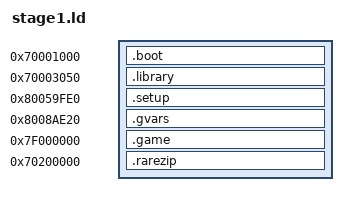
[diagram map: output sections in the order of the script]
/*OUTPUT_FORMAT ("elf32-bigmips")*/
OUTPUT_ARCH (mips)

SECTIONS
{
	setupSegmentStart = 0x80059fe0;
	setupSegmentRomStart = 0x39850;
	rarezipSegmentRomStart = 0x4e850;
	ziplistSegmentRomStart = 0x4fc40;

	.boot 0x70001000 : AT(0) {
		src/boot/boot.o (.text);
		src/boot/boot.o (.data);
	}

	.library 0x70003050 : AT(SIZEOF(.boot)) {
		src/library/library_03050.o (.text);
		src/library/library_034f0.o (.text);
		src/library/library_03ee0.o (.text);
		src/library/library_03fb0.o (.text);
		src/library/library_04320.o (.text);
		src/library/library_04790.o (.text);
		src/library/library_04840.o (.text);
		src/library/library_04a80.o (.text);
		src/library/library_05e40.o (.text);
		src/library/library_06100.o (.text);
		src/library/library_06330.o (.text);
		src/library/library_06440.o (.text);
		src/library/library_06550.o (.text);
		src/library/library_070d0.o (.text);
		src/library/library_074f0.o (.text);
		src/library/library_08a20.o (.text);
		src/library/library_09660.o (.text);
		src/library/library_0bfb0.o (.text);
		src/library/library_0c000.o (.text);
		src/library/library_0d0a0.o (.text);
		src/library/library_0d520.o (.text);
		src/library/library_0e9d0.o (.text);
		src/library/library_11420.o (.text);
		src/library/library_121e0.o (.text);
		src/library/library_126b0.o (.text);
		src/library/library_12dc0.o (.text);
		src/library/library_13130.o (.text);
		src/library/library_13710.o (.text);
		src/library/library_13750.o (.text);
		src/library/library_13790.o (.text);
		src/library/library_13900.o (.text);
		src/library/library_15860.o (.text);
		src/library/library_159b0.o (.text);
		src/library/library_16110.o (.text);
		src/library/library_1a500.o (.text);
		src/library/library_233c0.o (.text);
		src/library/library_2f490.o (.text);
		src/library/library_2fa00.o (.text);
		src/library/library_2faf0.o (.text);
		src/library/library_2fba0.o (.text);
		src/library/library_2fc60.o (.text);
		src/library/library_30ce0.o (.text);
		src/library/library_317f0.o (.text);
		src/library/library_37650.o (.text);
		src/library/library_37b00.o (.text);
		src/library/library_38d10.o (.text);
		src/library/library_38d30.o (.text);
		src/library/library_39c80.o (.text);
		src/library/library_39f70.o (.text);
		src/library/library_39fc0.o (.text);
		src/library/library_39fe0.o (.text);
		src/library/library_3a100.o (.text);
		src/library/library_3c430.o (.text);
		src/library/library_3c4d0.o (.text);
		src/library/library_3ccf0.o (.text);
		src/library/library_3cdc0.o (.text);
		src/library/library_3cef0.o (.text);
		src/library/library_3d280.o (.text);
		src/library/library_3e3e0.o (.text);
		src/library/library_3e730.o (.text);
		src/library/library_43dd0.o (.text);
		src/library/library_446d0.o (.text);
		src/library/library_44bc0.o (.text);
		src/library/library_44f60.o (.text);
		src/library/library_45ed0.o (.text);
		src/library/library_461c0.o (.text);
		src/library/library_46650.o (.text);
		src/library/library_47550.o (.text);
		src/library/library_47a90.o (.text);
		src/library/library_47d20.o (.text);
		src/library/library_48120.o (.text);
		src/library/library_48150.o (.text);
		src/library/library_481d0.o (.text);
		src/library/library_481e0.o (.text);
		src/library/library_48520.o (.text);
		src/library/library_485e0.o (.text);
		src/library/library_48650.o (.text);
		src/library/library_48830.o (.text);
		src/library/library_488e0.o (.text);
		src/library/library_48b20.o (.text);
		src/library/library_48c00.o (.text);
		src/library/library_48cd0.o (.text);
		src/library/library_48dc0.o (.text);
		src/library/library_48ef0.o (.text);
		src/library/library_48f50.o (.text);
		src/library/library_490b0.o (.text);
		src/library/library_491b0.o (.text);
		src/library/library_49640.o (.text);
		src/library/library_49780.o (.text);
		src/library/library_49a90.o (.text);
		src/library/library_49c20.o (.text);
		src/library/library_4a360.o (.text);
		src/library/library_4a5e0.o (.text);
		src/library/library_4a680.o (.text);
		src/library/library_4a810.o (.text);
		src/library/library_4a980.o (.text);
		src/library/library_4acc0.o (.text);
		src/library/library_4ace0.o (.text);
		src/library/library_4ad30.o (.text);
		src/library/library_4ad80.o (.text);
		src/library/library_4ae00.o (.text);
		src/library/library_4b160.o (.text);
		src/library/library_4b170.o (.text);
		src/library/library_4b480.o (.text);
		src/library/library_4b500.o (.text);
		src/library/library_4b550.o (.text);
		src/library/library_4b5e0.o (.text);
		src/library/library_4ba90.o (.text);
		src/library/library_4c090.o (.text);
		src/library/library_4cc10.o (.text);
		src/library/library_4cde0.o (.text);
		src/library/library_4ce60.o (.text);
		src/library/library_4d000.o (.text);
		src/library/library_4d480.o (.text);
		src/library/library_4d6f0.o (.text);
		src/library/library_4e270.o (.text);
		src/library/library_4e3c0.o (.text);
		src/library/library_4e470.o (.text);
		src/library/library_4e530.o (.text);
		src/library/library_4e690.o (.text);
		src/library/library_4f350.o (.text);
		src/library/library_4f400.o (.text);
		src/library/library_4f5e0.o (.text);
		src/library/library_4fe20.o (.text);
		src/library/library_4fff0.o (.text);
		src/library/library_50090.o (.text);
		src/library/library_50130.o (.text);
		src/library/library_50480.o (.text);
		src/library/library_50a00.o (.text);
		src/library/library_50f20.o (.text);
		src/library/library_513b0.o (.text);
		src/library/library_51880.o (.text);
		src/library/library_51890.o (.text);
		src/library/library_51900.o (.text);
		src/library/library_51a60.o (.text);
		src/library/library_51c10.o (.text);
		src/library/library_51c60.o (.text);
		src/library/library_51d50.o (.text);
		src/library/library_51ec0.o (.text);
		src/library/library_52070.o (.text);
		src/library/library_52360.o (.text);

		src/library/library_03050.o (.rodata);
		src/library/library_034f0.o (.rodata);
		src/library/library_03ee0.o (.rodata);
		src/library/library_03fb0.o (.rodata);
		src/library/library_04320.o (.rodata);
		src/library/library_04790.o (.rodata);
		src/library/library_04840.o (.rodata);
		src/library/library_04a80.o (.rodata);
		src/library/library_05e40.o (.rodata);
		src/library/library_06100.o (.rodata);
		src/library/library_06330.o (.rodata);
		src/library/library_06440.o (.rodata);
		src/library/library_06550.o (.rodata);
		src/library/library_070d0.o (.rodata);
		src/library/library_074f0.o (.rodata);
		src/library/library_08a20.o (.rodata);
		src/library/library_09660.o (.rodata);
		src/library/library_0bfb0.o (.rodata);
		src/library/library_0c000.o (.rodata);
		src/library/library_0d0a0.o (.rodata);
		src/library/library_0d520.o (.rodata);
		src/library/library_0e9d0.o (.rodata);
		src/library/library_11420.o (.rodata);
		src/library/library_121e0.o (.rodata);
		src/library/library_126b0.o (.rodata);
		src/library/library_12dc0.o (.rodata);
		src/library/library_13130.o (.rodata);
		src/library/library_13710.o (.rodata);
		src/library/library_13750.o (.rodata);
		src/library/library_13790.o (.rodata);
		src/library/library_13900.o (.rodata);
		src/library/library_15860.o (.rodata);
		src/library/library_159b0.o (.rodata);
		src/library/library_16110.o (.rodata);
		src/library/library_1a500.o (.rodata);
		src/library/library_233c0.o (.rodata);
		src/library/library_2f490.o (.rodata);
		src/library/library_2fa00.o (.rodata);
		src/library/library_2faf0.o (.rodata);
		src/library/library_2fba0.o (.rodata);
		src/library/library_2fc60.o (.rodata);
		src/library/library_30ce0.o (.rodata);
		src/library/library_317f0.o (.rodata);
		src/library/library_37650.o (.rodata);
		src/library/library_37b00.o (.rodata);
		src/library/library_38d10.o (.rodata);
		src/library/library_38d30.o (.rodata);
		src/library/library_39c80.o (.rodata);
		src/library/library_39f70.o (.rodata);
		src/library/library_39fc0.o (.rodata);
		src/library/library_39fe0.o (.rodata);
		src/library/library_3a100.o (.rodata);
		src/library/library_3c430.o (.rodata);
		src/library/library_3c4d0.o (.rodata);
		src/library/library_3ccf0.o (.rodata);
		src/library/library_3cdc0.o (.rodata);
		src/library/library_3cef0.o (.rodata);
		src/library/library_3d280.o (.rodata);
		src/library/library_3e3e0.o (.rodata);
		src/library/library_3e730.o (.rodata);
		src/library/library_43dd0.o (.rodata);
		src/library/library_446d0.o (.rodata);
		src/library/library_44bc0.o (.rodata);
		src/library/library_44f60.o (.rodata);
		src/library/library_45ed0.o (.rodata);
		src/library/library_461c0.o (.rodata);
		src/library/library_46650.o (.rodata);
		src/library/library_47550.o (.rodata);
		src/library/library_47a90.o (.rodata);
		src/library/library_47d20.o (.rodata);
		src/library/library_48120.o (.rodata);
		src/library/library_48150.o (.rodata);
		src/library/library_481d0.o (.rodata);
		src/library/library_481e0.o (.rodata);
		src/library/library_48520.o (.rodata);
		src/library/library_485e0.o (.rodata);
		src/library/library_48650.o (.rodata);
		src/library/library_48830.o (.rodata);
		src/library/library_488e0.o (.rodata);
		src/library/library_48b20.o (.rodata);
		src/library/library_48c00.o (.rodata);
		src/library/library_48cd0.o (.rodata);
		src/library/library_48dc0.o (.rodata);
		src/library/library_48ef0.o (.rodata);
		src/library/library_48f50.o (.rodata);
		src/library/library_490b0.o (.rodata);
		src/library/library_491b0.o (.rodata);
		src/library/library_49640.o (.rodata);
		src/library/library_49780.o (.rodata);
		src/library/library_49a90.o (.rodata);
		src/library/library_49c20.o (.rodata);
		src/library/library_4a360.o (.rodata);
		src/library/library_4a5e0.o (.rodata);
		src/library/library_4a680.o (.rodata);
		src/library/library_4a810.o (.rodata);
		src/library/library_4a980.o (.rodata);
		src/library/library_4acc0.o (.rodata);
		src/library/library_4ace0.o (.rodata);
		src/library/library_4ad30.o (.rodata);
		src/library/library_4ad80.o (.rodata);
		src/library/library_4ae00.o (.rodata);
		src/library/library_4b160.o (.rodata);
		src/library/library_4b170.o (.rodata);
		src/library/library_4b480.o (.rodata);
		src/library/library_4b500.o (.rodata);
		src/library/library_4b550.o (.rodata);
		src/library/library_4b5e0.o (.rodata);
		src/library/library_4ba90.o (.rodata);
		src/library/library_4c090.o (.rodata);
		src/library/library_4cc10.o (.rodata);
		src/library/library_4cde0.o (.rodata);
		src/library/library_4ce60.o (.rodata);
		src/library/library_4d000.o (.rodata);
		src/library/library_4d480.o (.rodata);
		src/library/library_4d6f0.o (.rodata);
		src/library/library_4e270.o (.rodata);
		src/library/library_4e3c0.o (.rodata);
		src/library/library_4e470.o (.rodata);
		src/library/library_4e530.o (.rodata);
		src/library/library_4e690.o (.rodata);
		src/library/library_4f350.o (.rodata);
		src/library/library_4f400.o (.rodata);
		src/library/library_4f5e0.o (.rodata);
		src/library/library_4fe20.o (.rodata);
		src/library/library_4fff0.o (.rodata);
		src/library/library_50090.o (.rodata);
		src/library/library_50130.o (.rodata);
		src/library/library_50480.o (.rodata);
		src/library/library_50a00.o (.rodata);
		src/library/library_50f20.o (.rodata);
		src/library/library_513b0.o (.rodata);
		src/library/library_51880.o (.rodata);
		src/library/library_51890.o (.rodata);
		src/library/library_51900.o (.rodata);
		src/library/library_51a60.o (.rodata);
		src/library/library_51c10.o (.rodata);
		src/library/library_51c60.o (.rodata);
		src/library/library_51d50.o (.rodata);
		src/library/library_51ec0.o (.rodata);
		src/library/library_52070.o (.rodata);
		src/library/library_52360.o (.rodata);
	}

	.setup 0x80059fe0 : AT(SIZEOF(.boot) + SIZEOF(.library)) {
		src/setup/setup_000000.o (.data);
		src/setup/inventory.o (.data);
		src/setup/setup_0160b0.o (.data);
		src/setup/ailists.o (.data);
		src/setup/setup_020df0.o (.data);
	}

	.gvars 0x8008ae20 : AT(SIZEOF(.boot) + SIZEOF(.library) + SIZEOF(.setup)) {
		src/gvars/gvars.o (.data);
	}

	.game 0x7f000000 : AT(SIZEOF(.boot) + SIZEOF(.library) + SIZEOF(.setup) + SIZEOF(.gvars)) {
		src/game/game_000000.o (.text);
		src/game/game_000090.o (.text);
		src/game/game_000130.o (.text);
		src/game/game_000850.o (.text);
		src/game/game_000860.o (.text);
		src/game/game_000870.o (.text);
		src/game/game_000880.o (.text);
		src/game/game_0008e0.o (.text);
		src/game/game_0008f0.o (.text);
		src/game/game_000900.o (.text);
		src/game/game_000910.o (.text);
		src/game/game_000920.o (.text);
		src/game/game_005fd0.o (.text);
		src/game/game_00b190.o (.text);
		src/game/game_00b200.o (.text);
		src/game/game_00b820.o (.text);
		src/game/game_00c240.o (.text);
		src/game/game_00c490.o (.text);
		src/game/game_0109d0.o (.text);
		src/game/game_011110.o (.text);
		src/game/game_0125a0.o (.text);
		src/game/game_013260.o (.text);
		src/game/game_013540.o (.text);
		src/game/game_014f10.o (.text);
		src/game/game_015010.o (.text);
		src/game/game_0150a0.o (.text);
		src/game/game_015260.o (.text);
		src/game/game_015270.o (.text);
		src/game/game_015280.o (.text);
		src/game/game_015400.o (.text);
		src/game/game_015410.o (.text);
		src/game/game_015420.o (.text);
		src/game/game_015470.o (.text);
		src/game/game_01d860.o (.text);
		src/game/game_01d9f0.o (.text);
		src/game/chr/chr.o (.text);
		src/game/chr/chrai.o (.text);
		src/game/chr/chraicommands.o (.text);
		src/game/game_0601b0.o (.text);
		src/game/game_066310.o (.text);
		src/game/game_096750.o (.text);
		src/game/game_097890.o (.text);
		src/game/game_097970.o (.text);
		src/game/game_097a50.o (.text);
		src/game/game_0abe70.o (.text);
		src/game/game_0b0420.o (.text);
		src/game/game_0b2150.o (.text);
		src/game/game_0b28d0.o (.text);
		src/game/game_0c3620.o (.text);
		src/game/game_0c37d0.o (.text);
		src/game/game_0c79f0.o (.text);
		src/game/game_0cf150.o (.text);
		src/game/game_0d1fe0.o (.text);
		src/game/game_0d4690.o (.text);
		src/game/game_0dcdb0.o (.text);
		src/game/game_0f09f0.o (.text);
		src/game/game_102240.o (.text);
		src/game/game_106d40.o (.text);
		src/game/game_107fb0.o (.text);
		src/game/game_10ccd0.o (.text);
		src/game/game_111600.o (.text);
		src/game/game_113220.o (.text);
		src/game/game_114240.o (.text);
		src/game/game_115ab0.o (.text);
		src/game/game_11ecf0.o (.text);
		src/game/game_128f30.o (.text);
		src/game/game_129900.o (.text);
		src/game/game_150820.o (.text);
		src/game/game_152710.o (.text);
		src/game/game_152fa0.o (.text);
		src/game/game_157db0.o (.text);
		src/game/game_165670.o (.text);
		src/game/game_1668e0.o (.text);
		src/game/game_16cfa0.o (.text);
		src/game/game_16e810.o (.text);
		src/game/game_175f50.o (.text);
		src/game/game_175f90.o (.text);
		src/game/game_176000.o (.text);
		src/game/game_176080.o (.text);
		src/game/game_176d70.o (.text);
		src/game/game_187770.o (.text);
		src/game/game_197600.o (.text);
		src/game/game_1999b0.o (.text);
		src/game/game_19c990.o (.text);
		src/game/game_1a3340.o (.text);
		src/game/game_1a78b0.o (.text);

		src/game/game_000000.o (.rodata);
		src/game/game_000090.o (.rodata);
		src/game/game_000130.o (.rodata);
		src/game/game_000850.o (.rodata);
		src/game/game_000860.o (.rodata);
		src/game/game_000870.o (.rodata);
		src/game/game_000880.o (.rodata);
		src/game/game_0008e0.o (.rodata);
		src/game/game_0008f0.o (.rodata);
		src/game/game_000900.o (.rodata);
		src/game/game_000910.o (.rodata);
		src/game/game_000920.o (.rodata);
		src/game/game_005fd0.o (.rodata);
		src/game/game_00b190.o (.rodata);
		src/game/game_00b200.o (.rodata);
		src/game/game_00b820.o (.rodata);
		src/game/game_00c240.o (.rodata);
		src/game/game_00c490.o (.rodata);
		src/game/game_0109d0.o (.rodata);
		src/game/game_011110.o (.rodata);
		src/game/game_0125a0.o (.rodata);
		src/game/game_013260.o (.rodata);
		src/game/game_013540.o (.rodata);
		src/game/game_014f10.o (.rodata);
		src/game/game_015010.o (.rodata);
		src/game/game_0150a0.o (.rodata);
		src/game/game_015260.o (.rodata);
		src/game/game_015270.o (.rodata);
		src/game/game_015280.o (.rodata);
		src/game/game_015400.o (.rodata);
		src/game/game_015410.o (.rodata);
		src/game/game_015420.o (.rodata);
		src/game/game_015470.o (.rodata);
		src/game/game_01d860.o (.rodata);
		src/game/game_01d9f0.o (.rodata);
		src/game/chr/chr.o (.rodata);
		src/game/chr/chrai.o (.rodata);
		src/game/chr/chraicommands.o (.rodata);
		src/game/game_0601b0.o (.rodata);
		src/game/game_066310.o (.rodata);
		src/game/game_096750.o (.rodata);
		src/game/game_097890.o (.rodata);
		src/game/game_097970.o (.rodata);
		src/game/game_097a50.o (.rodata);
		src/game/game_0abe70.o (.rodata);
		src/game/game_0b0420.o (.rodata);
		src/game/game_0b2150.o (.rodata);
		src/game/game_0b28d0.o (.rodata);
		src/game/game_0c3620.o (.rodata);
		src/game/game_0c37d0.o (.rodata);
		src/game/game_0c79f0.o (.rodata);
		src/game/game_0cf150.o (.rodata);
		src/game/game_0d1fe0.o (.rodata);
		src/game/game_0d4690.o (.rodata);
		src/game/game_0dcdb0.o (.rodata);
		src/game/game_0f09f0.o (.rodata);
		src/game/game_102240.o (.rodata);
		src/game/game_106d40.o (.rodata);
		src/game/game_107fb0.o (.rodata);
		src/game/game_10ccd0.o (.rodata);
		src/game/game_111600.o (.rodata);
		src/game/game_113220.o (.rodata);
		src/game/game_114240.o (.rodata);
		src/game/game_115ab0.o (.rodata);
		src/game/game_11ecf0.o (.rodata);
		src/game/game_128f30.o (.rodata);
		src/game/game_129900.o (.rodata);
		src/game/game_150820.o (.rodata);
		src/game/game_152710.o (.rodata);
		src/game/game_152fa0.o (.rodata);
		src/game/game_157db0.o (.rodata);
		src/game/game_165670.o (.rodata);
		src/game/game_1668e0.o (.rodata);
		src/game/game_16cfa0.o (.rodata);
		src/game/game_16e810.o (.rodata);
		src/game/game_175f50.o (.rodata);
		src/game/game_175f90.o (.rodata);
		src/game/game_176000.o (.rodata);
		src/game/game_176080.o (.rodata);
		src/game/game_176d70.o (.rodata);
		src/game/game_187770.o (.rodata);
		src/game/game_197600.o (.rodata);
		src/game/game_1999b0.o (.rodata);
		src/game/game_19c990.o (.rodata);
		src/game/game_1a3340.o (.rodata);
		src/game/game_1a78b0.o (.rodata);
	}

	.rarezip 0x70200000 : AT(SIZEOF(.boot) + SIZEOF(.library) + SIZEOF(.setup) + SIZEOF(.gvars) + SIZEOF(.game)) {
		src/rarezip/rarezip.o (.text);
		src/rarezip/rarezip.o (.data);
	}

	/DISCARD/ : {
		* (.MIPS.abiflags);
		* (.options);
		* (.gnu.attributes);
		* (.pdr);
		* (.mdebug);
		* (.gptab.bss);
		* (.gptab.data);
		* (.reginfo);
	}
}
